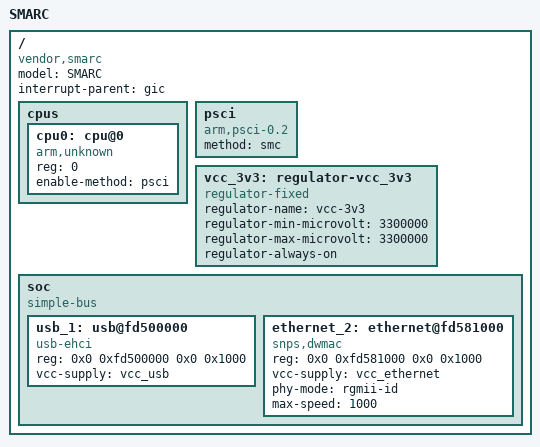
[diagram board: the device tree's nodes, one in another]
/dts-v1/;

/* Generated by @dt_architect — PDF-to-Gadget Pipeline
 * Board: SMARC
 * SoC  : Unknown SoC
 * Arch : arm64 (Unknown)
 * Date : auto-generated
 */

#include <dt-bindings/interrupt-controller/arm-gic.h>
#include <dt-bindings/gpio/gpio.h>

/ {
	compatible = "vendor,smarc", "vendor,unknown-soc";
	model = "SMARC";
	#address-cells = <2>;
	#size-cells = <2>;
	interrupt-parent = <&gic>;

	cpus {
		#address-cells = <1>;
		#size-cells = <0>;

		cpu0: cpu@0 {
			device_type = "cpu";
			compatible = "arm,unknown";
			reg = <0>;
			enable-method = "psci";
		};
	};

	psci {
		compatible = "arm,psci-0.2";
		method = "smc";
	};

	/* ── Power Regulators ─────────────────────────────── */
	vcc_3v3: regulator-vcc_3v3 {
		compatible = "regulator-fixed";
		regulator-name = "vcc-3v3";
		regulator-min-microvolt = <3300000>;
		regulator-max-microvolt = <3300000>;
		regulator-always-on;
	};

	/* ── Simple Bus ──────────────────────────────────── */
	soc: soc {
		compatible = "simple-bus";
		#address-cells = <2>;
		#size-cells = <2>;
		ranges;

		usb_1: usb@fd500000 {
			compatible = "usb-ehci";
			reg = <0x0 0xfd500000 0x0 0x1000>;
			#address-cells = <1>;
			#size-cells = <0>;
			status = "okay";
			vcc-supply = <&vcc_usb>;
			/* USB peripheral on USB */
		};

		ethernet_2: ethernet@fd581000 {
			compatible = "snps,dwmac";
			reg = <0x0 0xfd581000 0x0 0x1000>;
			#address-cells = <1>;
			#size-cells = <0>;
			status = "okay";
			vcc-supply = <&vcc_ethernet>;
			/* ETHERNET peripheral on ETHERNET */
			clock-names = "stmmaceth", "pclk", "ptp_ref";
			phy-mode = "rgmii-id";
			max-speed = <1000>;
		};
	};
};
